AUTOSAR XML (schema 3-2-1)
package /SeatHeater/SeatSensorRight_swc
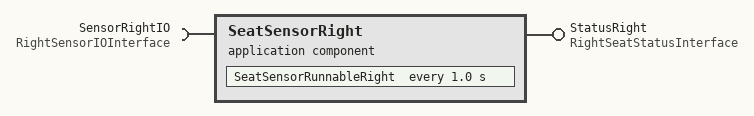
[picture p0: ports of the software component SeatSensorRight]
  application software component type SeatSensorRight
    require port SensorRightIO: unqueued-provider-com-spec{data-element=RightSensorValue, alive-timeout=60.0}, provided-interface=RightSensorIOInterface
    provide port StatusRight: unqueued-provider-com-spec{data-element=PassengerOnRightSeat, alive-timeout=60.0}, provided-interface=RightSeatStatusInterface
  internal behavior SeatSensorRightBehavior: component=SeatSensorRight
    timing event SeatSensorRightEvent: start-on-event=SeatSensorRunnableRight, period=1.0
    runnable SeatSensorRunnableRight: can-be-invoked-concurrently=true
      data read access SeatSensorRightIOAccess: data-element=SensorRightIO.RightSensorValue
      data write access SeatSensorRightStatusAccess: data-element=StatusRight.PassengerOnRightSeat
  swc implementation SeatSensorRightImplementation: behavior=SeatSensorRightBehavior
